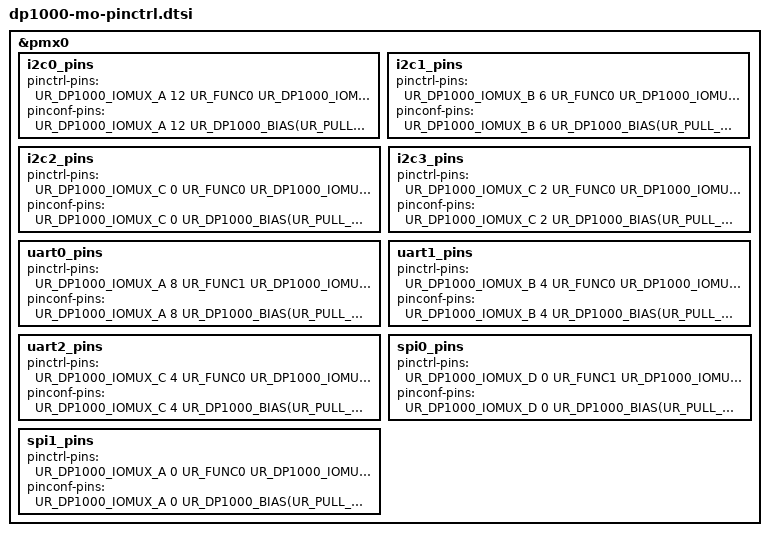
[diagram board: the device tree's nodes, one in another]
// SPDX-License-Identifier: GPL-2.0
/*
 * Copyright(C) 2025 UltraRISC Technology (Shanghai) Co., Ltd.
 */

#include <dt-bindings/pinctrl/ur-dp1000-pinctrl.h>
#include "dp1000.dtsi"

&pmx0 {
	i2c0_pins: i2c0_pins {
		pinctrl-pins = <
		UR_DP1000_IOMUX_A  12  UR_FUNC0
		UR_DP1000_IOMUX_A  13  UR_FUNC0
		>;

		pinconf-pins = <
		UR_DP1000_IOMUX_A  12  UR_DP1000_BIAS(UR_PULL_UP, UR_DRIVE_DEF)
		UR_DP1000_IOMUX_A  13  UR_DP1000_BIAS(UR_PULL_UP, UR_DRIVE_DEF)
		>;
	};

	i2c1_pins: i2c1_pins {
		pinctrl-pins = <
		UR_DP1000_IOMUX_B  6  UR_FUNC0
		UR_DP1000_IOMUX_B  7  UR_FUNC0
		>;

		pinconf-pins = <
		UR_DP1000_IOMUX_B  6  UR_DP1000_BIAS(UR_PULL_UP, UR_DRIVE_DEF)
		UR_DP1000_IOMUX_B  7  UR_DP1000_BIAS(UR_PULL_UP, UR_DRIVE_DEF)
		>;
	};

	i2c2_pins: i2c2_pins {
		pinctrl-pins = <
		UR_DP1000_IOMUX_C  0  UR_FUNC0
		UR_DP1000_IOMUX_C  1  UR_FUNC0
		>;

		pinconf-pins = <
		UR_DP1000_IOMUX_C  0  UR_DP1000_BIAS(UR_PULL_UP, UR_DRIVE_DEF)
		UR_DP1000_IOMUX_C  1  UR_DP1000_BIAS(UR_PULL_UP, UR_DRIVE_DEF)
		>;
	};

	i2c3_pins: i2c3_pins {
		pinctrl-pins = <
		UR_DP1000_IOMUX_C  2  UR_FUNC0
		UR_DP1000_IOMUX_C  3  UR_FUNC0
		>;

		pinconf-pins = <
		UR_DP1000_IOMUX_C  2  UR_DP1000_BIAS(UR_PULL_UP, UR_DRIVE_DEF)
		UR_DP1000_IOMUX_C  3  UR_DP1000_BIAS(UR_PULL_UP, UR_DRIVE_DEF)
		>;
	};

	uart0_pins: uart0_pins {
		pinctrl-pins = <
		UR_DP1000_IOMUX_A  8  UR_FUNC1
		UR_DP1000_IOMUX_A  9  UR_FUNC1
		>;

		pinconf-pins = <
		UR_DP1000_IOMUX_A  8  UR_DP1000_BIAS(UR_PULL_UP, UR_DRIVE_DEF)
		UR_DP1000_IOMUX_A  9  UR_DP1000_BIAS(UR_PULL_UP, UR_DRIVE_DEF)
		>;
	};

	uart1_pins: uart1_pins {
		pinctrl-pins = <
		UR_DP1000_IOMUX_B  4  UR_FUNC0
		UR_DP1000_IOMUX_B  5  UR_FUNC0
		>;

		pinconf-pins = <
		UR_DP1000_IOMUX_B  4  UR_DP1000_BIAS(UR_PULL_UP, UR_DRIVE_DEF)
		UR_DP1000_IOMUX_B  5  UR_DP1000_BIAS(UR_PULL_UP, UR_DRIVE_DEF)
		>;
	};

	uart2_pins: uart2_pins {
		pinctrl-pins = <
		UR_DP1000_IOMUX_C  4  UR_FUNC0
		UR_DP1000_IOMUX_C  5  UR_FUNC0
		>;

		pinconf-pins = <
		UR_DP1000_IOMUX_C  4  UR_DP1000_BIAS(UR_PULL_UP, UR_DRIVE_DEF)
		UR_DP1000_IOMUX_C  5  UR_DP1000_BIAS(UR_PULL_UP, UR_DRIVE_DEF)
		>;
	};

	spi0_pins: spi0_pins {
		pinctrl-pins = <
		UR_DP1000_IOMUX_D  0  UR_FUNC1
		UR_DP1000_IOMUX_D  1  UR_FUNC1
		UR_DP1000_IOMUX_D  2  UR_FUNC1
		UR_DP1000_IOMUX_D  3  UR_FUNC1
		UR_DP1000_IOMUX_D  4  UR_FUNC1
		UR_DP1000_IOMUX_D  5  UR_FUNC1
		UR_DP1000_IOMUX_D  6  UR_FUNC1
		UR_DP1000_IOMUX_D  7  UR_FUNC1
		>;

		pinconf-pins = <
		UR_DP1000_IOMUX_D  0  UR_DP1000_BIAS(UR_PULL_UP, UR_DRIVE_DEF)
		UR_DP1000_IOMUX_D  1  UR_DP1000_BIAS(UR_PULL_UP, UR_DRIVE_DEF)
		UR_DP1000_IOMUX_D  2  UR_DP1000_BIAS(UR_PULL_UP, UR_DRIVE_DEF)
		UR_DP1000_IOMUX_D  3  UR_DP1000_BIAS(UR_PULL_UP, UR_DRIVE_DEF)
		UR_DP1000_IOMUX_D  4  UR_DP1000_BIAS(UR_PULL_UP, UR_DRIVE_DEF)
		UR_DP1000_IOMUX_D  5  UR_DP1000_BIAS(UR_PULL_UP, UR_DRIVE_DEF)
		UR_DP1000_IOMUX_D  6  UR_DP1000_BIAS(UR_PULL_UP, UR_DRIVE_DEF)
		UR_DP1000_IOMUX_D  7  UR_DP1000_BIAS(UR_PULL_UP, UR_DRIVE_DEF)
		>;
	};

	spi1_pins: spi1_pins {
		pinctrl-pins = <
		UR_DP1000_IOMUX_A  0  UR_FUNC0
		UR_DP1000_IOMUX_A  1  UR_FUNC0
		UR_DP1000_IOMUX_A  2  UR_FUNC0
		UR_DP1000_IOMUX_A  3  UR_FUNC0
		>;

		pinconf-pins = <
		UR_DP1000_IOMUX_A  0  UR_DP1000_BIAS(UR_PULL_UP, UR_DRIVE_DEF)
		UR_DP1000_IOMUX_A  1  UR_DP1000_BIAS(UR_PULL_UP, UR_DRIVE_DEF)
		UR_DP1000_IOMUX_A  2  UR_DP1000_BIAS(UR_PULL_UP, UR_DRIVE_DEF)
		UR_DP1000_IOMUX_A  3  UR_DP1000_BIAS(UR_PULL_UP, UR_DRIVE_DEF)
		>;
	};
};
